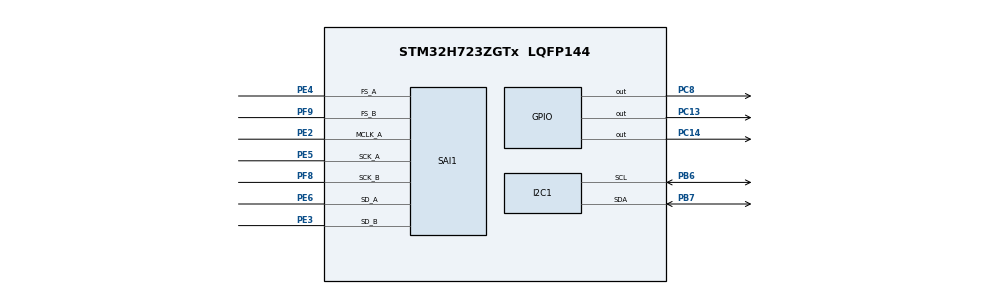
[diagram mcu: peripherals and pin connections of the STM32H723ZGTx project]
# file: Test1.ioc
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Dma.Request0=SAI1_A
Dma.Request1=SAI1_B
Dma.SAI1_A.0.Direction=DMA_MEMORY_TO_PERIPH
Dma.SAI1_A.0.EventEnable=DISABLE
Dma.SAI1_A.0.FIFOMode=DMA_FIFOMODE_ENABLE
Dma.SAI1_A.0.FIFOThreshold=DMA_FIFO_THRESHOLD_FULL
Dma.SAI1_A.0.Instance=DMA1_Stream0
Dma.SAI1_A.0.MemBurst=DMA_MBURST_SINGLE
Dma.SAI1_A.0.MemDataAlignment=DMA_MDATAALIGN_WORD
Dma.SAI1_A.0.MemInc=DMA_MINC_ENABLE
Dma.SAI1_A.0.Mode=DMA_CIRCULAR
Dma.SAI1_A.0.PeriphBurst=DMA_PBURST_SINGLE
Dma.SAI1_A.0.PeriphDataAlignment=DMA_PDATAALIGN_WORD
Dma.SAI1_A.0.PeriphInc=DMA_PINC_DISABLE
Dma.SAI1_A.0.Polarity=HAL_DMAMUX_REQ_GEN_RISING
Dma.SAI1_A.0.Priority=DMA_PRIORITY_LOW
Dma.SAI1_A.0.RequestNumber=1
Dma.SAI1_A.0.SignalID=NONE
Dma.SAI1_A.0.SyncEnable=DISABLE
Dma.SAI1_A.0.SyncPolarity=HAL_DMAMUX_SYNC_NO_EVENT
Dma.SAI1_A.0.SyncRequestNumber=1
Dma.SAI1_A.0.SyncSignalID=NONE
Dma.SAI1_B.1.Direction=DMA_PERIPH_TO_MEMORY
Dma.SAI1_B.1.EventEnable=ENABLE
Dma.SAI1_B.1.FIFOMode=DMA_FIFOMODE_DISABLE
Dma.SAI1_B.1.Instance=DMA1_Stream1
Dma.SAI1_B.1.MemDataAlignment=DMA_MDATAALIGN_WORD
Dma.SAI1_B.1.MemInc=DMA_MINC_ENABLE
Dma.SAI1_B.1.Mode=DMA_CIRCULAR
Dma.SAI1_B.1.PeriphDataAlignment=DMA_PDATAALIGN_WORD
Dma.SAI1_B.1.PeriphInc=DMA_PINC_DISABLE
Dma.SAI1_B.1.Polarity=HAL_DMAMUX_REQ_GEN_RISING
Dma.SAI1_B.1.Priority=DMA_PRIORITY_LOW
Dma.SAI1_B.1.RequestNumber=1
Dma.SAI1_B.1.SignalID=NONE
Dma.SAI1_B.1.SyncEnable=ENABLE
Dma.SAI1_B.1.SyncPolarity=HAL_DMAMUX_SYNC_RISING
Dma.SAI1_B.1.SyncRequestNumber=1
Dma.SAI1_B.1.SyncSignalID=NONE
I2C1.Timing=0x60404E72
Mcu.Family=STM32H7
Mcu.Name=STM32H723ZGTx
Mcu.Package=LQFP144
NVIC.DMA1_Stream0_IRQn=true\:0\:0\:false\:false\:true\:false\:true\:true
NVIC.DMA1_Stream1_IRQn=true\:0\:0\:false\:false\:true\:false\:true\:true
NVIC.DMAMUX1_OVR_IRQn=true\:0\:0\:false\:false\:true\:false\:true\:true
NVIC.PriorityGroup=NVIC_PRIORITYGROUP_4
NVIC.SAI1_IRQn=true\:0\:0\:false\:false\:true\:true\:true\:true
PA13(JTMS/SWDIO).Mode=Trace_Asynchronous_SW
PA13(JTMS/SWDIO).Signal=DEBUG_JTMS-SWDIO
PA14(JTCK/SWCLK).Mode=Trace_Asynchronous_SW
PA14(JTCK/SWCLK).Signal=DEBUG_JTCK-SWCLK
PB3(JTDO/TRACESWO).Mode=Trace_Asynchronous_SW
PB3(JTDO/TRACESWO).Signal=DEBUG_JTDO-SWO
PB6.Mode=I2C
PB6.Signal=I2C1_SCL
PB7.Mode=I2C
PB7.Signal=I2C1_SDA
PC13.Signal=GPIO_Output
PC14-OSC32_IN.Signal=GPIO_Output
PC8.Signal=GPIO_Output
PE2.Mode=SAI_A_MasterWithClock
PE2.Signal=SAI1_MCLK_A
PE3.Mode=SAI_B_AsyncSlave
PE3.Signal=SAI1_SD_B
PE4.Mode=SAI_A_MasterWithClock
PE4.Signal=SAI1_FS_A
PE5.Mode=SAI_A_MasterWithClock
PE5.Signal=SAI1_SCK_A
PE6.Mode=SAI_A_MasterWithClock
PE6.Signal=SAI1_SD_A
PF8.Mode=SAI_B_AsyncSlave
PF8.Signal=SAI1_SCK_B
PF9.Mode=SAI_B_AsyncSlave
PF9.Signal=SAI1_FS_B
PH0-OSC_IN.Mode=HSE-External-Oscillator
PH0-OSC_IN.Signal=RCC_OSC_IN
PH1-OSC_OUT.Mode=HSE-External-Oscillator
PH1-OSC_OUT.Signal=RCC_OSC_OUT
ProjectManager.HeapSize=0x200
ProjectManager.StackSize=0x400
ProjectManager.TargetToolchain=STM32CubeIDE
RCC.ADCFreq_Value=1536000
RCC.APB1Freq_Value=137500000
RCC.APB2Freq_Value=137500000
RCC.APB3Freq_Value=137500000
RCC.APB4Freq_Value=137500000
RCC.CortexFreq_Value=550000000
RCC.D1PPRE=RCC_APB3_DIV2
RCC.D2PPRE1=RCC_APB1_DIV2
RCC.D2PPRE2=RCC_APB2_DIV2
RCC.D3PPRE=RCC_APB4_DIV2
RCC.DIVM1=1
RCC.DIVM2=1
RCC.DIVM3=5
RCC.DIVN1=34
RCC.DIVN2=12
RCC.DIVN3=96
RCC.DIVP1=1
RCC.DIVP2=125
RCC.DIVP3=25
RCC.DIVQ1=25
RCC.HCLKFreq_Value=275000000
RCC.HPRE=RCC_HCLK_DIV2
RCC.HSE_VALUE=16000000
RCC.PLL2FRACN=0
RCC.PLL3FRACN=0
RCC.PLLFRACN=3072
RCC.PLLSourceVirtual=RCC_PLLSOURCE_HSE
RCC.SAI1CLockSelection=RCC_SAI1CLKSOURCE_PLL3
RCC.SYSCLKFreq_VALUE=550000000
RCC.SYSCLKSource=RCC_SYSCLKSOURCE_PLLCLK
RCC.USBFreq_Value=22000000
SAI1.AudioFrequency-SAI_A_MasterWithClock=SAI_AUDIO_FREQUENCY_48K
SAI1.DataSize-SAI_A_MasterWithClock=SAI_DATASIZE_24
SAI1.DataSize-SAI_B_AsyncSlave=SAI_DATASIZE_24
SAI1.ErrorAudioFreq-SAI_A_MasterWithClock=0.0 %
SAI1.FrameLength-SAI_A_MasterWithClock=256
SAI1.FrameLength-SAI_B_AsyncSlave=256
SAI1.Instance-SAI_A_MasterWithClock=SAI$Index_Block_A
SAI1.Instance-SAI_B_AsyncSlave=SAI$Index_Block_B
SAI1.MckOutput-SAI_A_MasterWithClock=SAI_MCK_OUTPUT_ENABLE
SAI1.NoDivider-SAI_A_MasterWithClock=SAI_MASTERDIVIDER_ENABLE
SAI1.RealAudioFreq-SAI_A_MasterWithClock=48.0 KHz
SAI1.SlotActive-SAI_A_MasterWithClock=0x0000FFFF
SAI1.SlotNumber-SAI_A_MasterWithClock=8
SAI1.SlotNumber-SAI_B_AsyncSlave=6
SAI1.SlotSize-SAI_A_MasterWithClock=SAI_SLOTSIZE_32B
SAI1.SlotSize-SAI_B_AsyncSlave=SAI_SLOTSIZE_32B
SAI1.VirtualMode-SAI_A_MasterWithClock=VM_MASTER
SAI1.VirtualMode-SAI_B_AsyncSlave=VM_SLAVE
SAI1.VirtualSlotActive-SAI_A_MasterWithClock=SAI_SLOTACTIVE_ALL
VP_SAI1_VP_$IpInstance_SYNCHRO_EXTERNAL.Mode=SynchroExternal
board=custom

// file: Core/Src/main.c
/* USER CODE BEGIN Header */
/**
  ******************************************************************************
  * @file           : main.c
  * @brief          : Main program body
  ******************************************************************************
  * @attention
  *
  * Copyright (c) 2024 STMicroelectronics.
  * All rights reserved.
  *
  * This software is licensed under terms that can be found in the LICENSE file
  * in the root directory of this software component.
  * If no LICENSE file comes with this software, it is provided AS-IS.
  *
  ******************************************************************************
  */
/* USER CODE END Header */
#include "main.h"

/* USER CODE BEGIN Includes */
#include "PCM3168A.h"
/* USER CODE END Includes */

I2C_HandleTypeDef hi2c1;

SAI_HandleTypeDef hsai_BlockA1;
SAI_HandleTypeDef hsai_BlockB1;
DMA_HandleTypeDef hdma_sai1_a;
DMA_HandleTypeDef hdma_sai1_b;

void SystemClock_Config(void);
void PeriphCommonClock_Config(void);
static void MX_GPIO_Init(void);
static void MX_DMA_Init(void);
static void MX_SAI1_Init(void);
static void MX_I2C1_Init(void);

int main(void)
{

  /* MCU Configuration--------------------------------------------------------*/

  /* Reset of all peripherals, Initializes the Flash interface and the Systick. */
  HAL_Init();

  /* USER CODE BEGIN Init */
  PCM3168A_Init();
  /* USER CODE END Init */

  /* Configure the system clock */
  SystemClock_Config();

/* Configure the peripherals common clocks */
  PeriphCommonClock_Config();

  /* Initialize all configured peripherals */
  MX_GPIO_Init();
  MX_DMA_Init();
  MX_SAI1_Init();
  MX_I2C1_Init();

  /* Infinite loop */
  /* USER CODE BEGIN WHILE */
  while (1)
  {
	  //HAL_GPIO_TogglePin (GPIOC, GPIO_PIN_8);
	  HAL_GPIO_TogglePin (GPIOC, GPIO_PIN_13);
	  HAL_Delay (500);   /* Insert delay 100 ms */
    /* USER CODE END WHILE */

  }
}

void SystemClock_Config(void)
{
  RCC_OscInitTypeDef RCC_OscInitStruct = {0};
  RCC_ClkInitTypeDef RCC_ClkInitStruct = {0};

  /** Supply configuration update enable
  */
  HAL_PWREx_ConfigSupply(PWR_LDO_SUPPLY);

  /** Configure the main internal regulator output voltage
  */
  __HAL_PWR_VOLTAGESCALING_CONFIG(PWR_REGULATOR_VOLTAGE_SCALE0);

  while(!__HAL_PWR_GET_FLAG(PWR_FLAG_VOSRDY)) {}

  /** Initializes the RCC Oscillators according to the specified parameters
  * in the RCC_OscInitTypeDef structure.
  */
  RCC_OscInitStruct.OscillatorType = RCC_OSCILLATORTYPE_HSE;
  RCC_OscInitStruct.HSEState = RCC_HSE_ON;
  RCC_OscInitStruct.PLL.PLLState = RCC_PLL_ON;
  RCC_OscInitStruct.PLL.PLLSource = RCC_PLLSOURCE_HSE;
  RCC_OscInitStruct.PLL.PLLM = 1;
  RCC_OscInitStruct.PLL.PLLN = 34;
  RCC_OscInitStruct.PLL.PLLP = 1;
  RCC_OscInitStruct.PLL.PLLQ = 25;
  RCC_OscInitStruct.PLL.PLLR = 2;
  RCC_OscInitStruct.PLL.PLLRGE = RCC_PLL1VCIRANGE_3;
  RCC_OscInitStruct.PLL.PLLVCOSEL = RCC_PLL1VCOWIDE;
  RCC_OscInitStruct.PLL.PLLFRACN = 3072;
  if (HAL_RCC_OscConfig(&RCC_OscInitStruct) != HAL_OK)
  {
    Error_Handler();
  }

  /** Initializes the CPU, AHB and APB buses clocks
  */
  RCC_ClkInitStruct.ClockType = RCC_CLOCKTYPE_HCLK|RCC_CLOCKTYPE_SYSCLK
                              |RCC_CLOCKTYPE_PCLK1|RCC_CLOCKTYPE_PCLK2
                              |RCC_CLOCKTYPE_D3PCLK1|RCC_CLOCKTYPE_D1PCLK1;
  RCC_ClkInitStruct.SYSCLKSource = RCC_SYSCLKSOURCE_PLLCLK;
  RCC_ClkInitStruct.SYSCLKDivider = RCC_SYSCLK_DIV1;
  RCC_ClkInitStruct.AHBCLKDivider = RCC_HCLK_DIV2;
  RCC_ClkInitStruct.APB3CLKDivider = RCC_APB3_DIV2;
  RCC_ClkInitStruct.APB1CLKDivider = RCC_APB1_DIV2;
  RCC_ClkInitStruct.APB2CLKDivider = RCC_APB2_DIV2;
  RCC_ClkInitStruct.APB4CLKDivider = RCC_APB4_DIV2;

  if (HAL_RCC_ClockConfig(&RCC_ClkInitStruct, FLASH_LATENCY_3) != HAL_OK)
  {
    Error_Handler();
  }
}

void PeriphCommonClock_Config(void)
{
  RCC_PeriphCLKInitTypeDef PeriphClkInitStruct = {0};

  /** Initializes the peripherals clock
  */
  PeriphClkInitStruct.PeriphClockSelection = RCC_PERIPHCLK_SAI1;
  PeriphClkInitStruct.PLL3.PLL3M = 5;
  PeriphClkInitStruct.PLL3.PLL3N = 96;
  PeriphClkInitStruct.PLL3.PLL3P = 25;
  PeriphClkInitStruct.PLL3.PLL3Q = 2;
  PeriphClkInitStruct.PLL3.PLL3R = 2;
  PeriphClkInitStruct.PLL3.PLL3RGE = RCC_PLL3VCIRANGE_1;
  PeriphClkInitStruct.PLL3.PLL3VCOSEL = RCC_PLL3VCOWIDE;
  PeriphClkInitStruct.PLL3.PLL3FRACN = 0;
  PeriphClkInitStruct.Sai1ClockSelection = RCC_SAI1CLKSOURCE_PLL3;
  if (HAL_RCCEx_PeriphCLKConfig(&PeriphClkInitStruct) != HAL_OK)
  {
    Error_Handler();
  }
}

static void MX_I2C1_Init(void)
{

  hi2c1.Instance = I2C1;
  hi2c1.Init.Timing = 0x60404E72;
  hi2c1.Init.OwnAddress1 = 0;
  hi2c1.Init.AddressingMode = I2C_ADDRESSINGMODE_7BIT;
  hi2c1.Init.DualAddressMode = I2C_DUALADDRESS_DISABLE;
  hi2c1.Init.OwnAddress2 = 0;
  hi2c1.Init.OwnAddress2Masks = I2C_OA2_NOMASK;
  hi2c1.Init.GeneralCallMode = I2C_GENERALCALL_DISABLE;
  hi2c1.Init.NoStretchMode = I2C_NOSTRETCH_DISABLE;
  if (HAL_I2C_Init(&hi2c1) != HAL_OK)
  {
    Error_Handler();
  }

  /** Configure Analogue filter
  */
  if (HAL_I2CEx_ConfigAnalogFilter(&hi2c1, I2C_ANALOGFILTER_ENABLE) != HAL_OK)
  {
    Error_Handler();
  }

  /** Configure Digital filter
  */
  if (HAL_I2CEx_ConfigDigitalFilter(&hi2c1, 0) != HAL_OK)
  {
    Error_Handler();
  }

}

static void MX_SAI1_Init(void)
{

  hsai_BlockA1.Instance = SAI1_Block_A;
  hsai_BlockA1.Init.Protocol = SAI_FREE_PROTOCOL;
  hsai_BlockA1.Init.AudioMode = SAI_MODEMASTER_TX;
  hsai_BlockA1.Init.DataSize = SAI_DATASIZE_24;
  hsai_BlockA1.Init.FirstBit = SAI_FIRSTBIT_MSB;
  hsai_BlockA1.Init.ClockStrobing = SAI_CLOCKSTROBING_FALLINGEDGE;
  hsai_BlockA1.Init.Synchro = SAI_ASYNCHRONOUS;
  hsai_BlockA1.Init.OutputDrive = SAI_OUTPUTDRIVE_DISABLE;
  hsai_BlockA1.Init.NoDivider = SAI_MASTERDIVIDER_ENABLE;
  hsai_BlockA1.Init.FIFOThreshold = SAI_FIFOTHRESHOLD_EMPTY;
  hsai_BlockA1.Init.AudioFrequency = SAI_AUDIO_FREQUENCY_48K;
  hsai_BlockA1.Init.SynchroExt = SAI_SYNCEXT_DISABLE;
  hsai_BlockA1.Init.MonoStereoMode = SAI_STEREOMODE;
  hsai_BlockA1.Init.CompandingMode = SAI_NOCOMPANDING;
  hsai_BlockA1.Init.TriState = SAI_OUTPUT_NOTRELEASED;
  hsai_BlockA1.Init.PdmInit.Activation = DISABLE;
  hsai_BlockA1.Init.PdmInit.MicPairsNbr = 0;
  hsai_BlockA1.Init.PdmInit.ClockEnable = SAI_PDM_CLOCK1_ENABLE;
  hsai_BlockA1.FrameInit.FrameLength = 256;
  hsai_BlockA1.FrameInit.ActiveFrameLength = 1;
  hsai_BlockA1.FrameInit.FSDefinition = SAI_FS_STARTFRAME;
  hsai_BlockA1.FrameInit.FSPolarity = SAI_FS_ACTIVE_LOW;
  hsai_BlockA1.FrameInit.FSOffset = SAI_FS_FIRSTBIT;
  hsai_BlockA1.SlotInit.FirstBitOffset = 0;
  hsai_BlockA1.SlotInit.SlotSize = SAI_SLOTSIZE_32B;
  hsai_BlockA1.SlotInit.SlotNumber = 8;
  hsai_BlockA1.SlotInit.SlotActive = 0x0000FFFF;
  if (HAL_SAI_Init(&hsai_BlockA1) != HAL_OK)
  {
    Error_Handler();
  }
  hsai_BlockB1.Instance = SAI1_Block_B;
  hsai_BlockB1.Init.Protocol = SAI_FREE_PROTOCOL;
  hsai_BlockB1.Init.AudioMode = SAI_MODESLAVE_RX;
  hsai_BlockB1.Init.DataSize = SAI_DATASIZE_24;
  hsai_BlockB1.Init.FirstBit = SAI_FIRSTBIT_MSB;
  hsai_BlockB1.Init.ClockStrobing = SAI_CLOCKSTROBING_FALLINGEDGE;
  hsai_BlockB1.Init.Synchro = SAI_ASYNCHRONOUS;
  hsai_BlockB1.Init.OutputDrive = SAI_OUTPUTDRIVE_DISABLE;
  hsai_BlockB1.Init.FIFOThreshold = SAI_FIFOTHRESHOLD_EMPTY;
  hsai_BlockB1.Init.SynchroExt = SAI_SYNCEXT_DISABLE;
  hsai_BlockB1.Init.MonoStereoMode = SAI_STEREOMODE;
  hsai_BlockB1.Init.CompandingMode = SAI_NOCOMPANDING;
  hsai_BlockB1.Init.TriState = SAI_OUTPUT_NOTRELEASED;
  hsai_BlockB1.Init.PdmInit.Activation = DISABLE;
  hsai_BlockB1.Init.PdmInit.MicPairsNbr = 0;
  hsai_BlockB1.Init.PdmInit.ClockEnable = SAI_PDM_CLOCK1_ENABLE;
  hsai_BlockB1.FrameInit.FrameLength = 256;
  hsai_BlockB1.FrameInit.ActiveFrameLength = 1;
  hsai_BlockB1.FrameInit.FSDefinition = SAI_FS_STARTFRAME;
  hsai_BlockB1.FrameInit.FSPolarity = SAI_FS_ACTIVE_LOW;
  hsai_BlockB1.FrameInit.FSOffset = SAI_FS_FIRSTBIT;
  hsai_BlockB1.SlotInit.FirstBitOffset = 0;
  hsai_BlockB1.SlotInit.SlotSize = SAI_SLOTSIZE_32B;
  hsai_BlockB1.SlotInit.SlotNumber = 6;
  hsai_BlockB1.SlotInit.SlotActive = 0x00000000;
  if (HAL_SAI_Init(&hsai_BlockB1) != HAL_OK)
  {
    Error_Handler();
  }

}

static void MX_DMA_Init(void)
{

  /* DMA controller clock enable */
  __HAL_RCC_DMA1_CLK_ENABLE();

  /* DMA interrupt init */
  /* DMA1_Stream0_IRQn interrupt configuration */
  HAL_NVIC_SetPriority(DMA1_Stream0_IRQn, 0, 0);
  HAL_NVIC_EnableIRQ(DMA1_Stream0_IRQn);
  /* DMA1_Stream1_IRQn interrupt configuration */
  HAL_NVIC_SetPriority(DMA1_Stream1_IRQn, 0, 0);
  HAL_NVIC_EnableIRQ(DMA1_Stream1_IRQn);
  /* DMAMUX1_OVR_IRQn interrupt configuration */
  HAL_NVIC_SetPriority(DMAMUX1_OVR_IRQn, 0, 0);
  HAL_NVIC_EnableIRQ(DMAMUX1_OVR_IRQn);

}

static void MX_GPIO_Init(void)
{
  GPIO_InitTypeDef GPIO_InitStruct = {0};

  /* GPIO Ports Clock Enable */
  __HAL_RCC_GPIOE_CLK_ENABLE();
  __HAL_RCC_GPIOC_CLK_ENABLE();
  __HAL_RCC_GPIOF_CLK_ENABLE();
  __HAL_RCC_GPIOH_CLK_ENABLE();
  __HAL_RCC_GPIOA_CLK_ENABLE();
  __HAL_RCC_GPIOB_CLK_ENABLE();

  /*Configure GPIO pin Output Level */
  HAL_GPIO_WritePin(GPIOC, GPIO_PIN_13|GPIO_PIN_14|GPIO_PIN_8, GPIO_PIN_RESET);

  /*Configure GPIO pins : PC13 PC14 PC8 */
  GPIO_InitStruct.Pin = GPIO_PIN_13|GPIO_PIN_14|GPIO_PIN_8;
  GPIO_InitStruct.Mode = GPIO_MODE_OUTPUT_PP;
  GPIO_InitStruct.Pull = GPIO_NOPULL;
  GPIO_InitStruct.Speed = GPIO_SPEED_FREQ_LOW;
  HAL_GPIO_Init(GPIOC, &GPIO_InitStruct);

}

void Error_Handler(void)
{
  __disable_irq();
  while (1)
  {
  }
}
